# GD32G5x3 register map
File version: 1.0
CPU: CM33 r2p1, little endian, MPU, FPU, 4 interrupt priority bits
Registers are 32-bit, read-write, reset 0x0 unless marked. A register's access mark holds for its fields unless they carry their own. Offsets are from the block's base; [hi:lo] are bit positions.

## QSPI — Quad-SPI interface
Base 0xA0001000
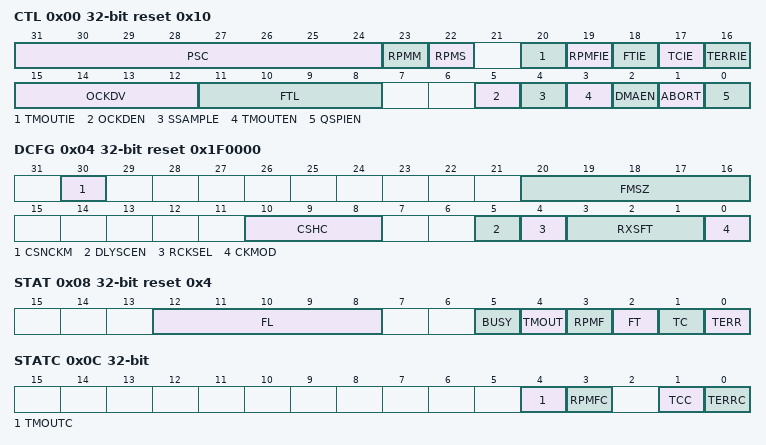
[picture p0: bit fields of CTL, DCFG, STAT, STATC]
0x00 CTL reset 0x10 — Control register
  [31:24] PSC — The clock prescaler of AHB clock for generating SCK
  [23] RPMM — Read polling match mode
  [22] RPMS — Read polling mode stop
  [20] TMOUTIE — Timeout interrupt enable
  [19] RPMFIE — Read polling mode match interrupt enable
  [18] FTIE — FIFO threshold interrupt enable
  [17] TCIE — Transfer complete interrupt enable
  [16] TERRIE — Transfer error interrupt enable
  [15:12] OCKDV — output clock delay value
  [11:8] FTL — FIFO threshold level
  [5] OCKDEN — Output clock delay enable when write data to flash
  [4] SSAMPLE — Sample delay
  [3] TMOUTEN — Timeout counter enable
  [2] DMAEN — DMA enable
  [1] ABORT — Abort request
  [0] QSPIEN — QSPI enable bit
0x04 DCFG reset 0x1F0000 — Device configuration register
  [30] CSNCKM — Select whether the CSN falls and rises one or two SCK clock cycles before the first SCK effective rising edge and after the last SCK effective rising edge
  [20:16] FMSZ — Flash memory size
  [10:8] CSHC — Chip select high cycle
  [5] DLYSCEN — Delay scan enable
  [4] RCKSEL — Receive clock select
  [3:1] RXSFT — Shift receive step if rececive data delay more than 0
  [0] CKMOD — This bit indicates the SCK level when QSPI is free
0x08 STAT access per field reset 0x4 — Status register
  [12:8] FL rw — FIFO level
  [5] BUSY ro — Busy flag
  [4] TMOUT ro — Timeout flag
  [3] RPMF ro — Read polling match flag
  [2] FT ro — FIFO threshold flag
  [1] TC ro — Transfer complete flag
  [0] TERR ro — Transfer error flag
0x0C STATC wo — Status clear register
  [4] TMOUTC — Clear timeout flag
  [3] RPMFC — Clear read polling mode match flag
  [1] TCC — Clear transfer complete flag
  [0] TERRC — Clear transfer error flag
0x10 DTLEN — Data length register
  [31:0] DTLEN — Data length
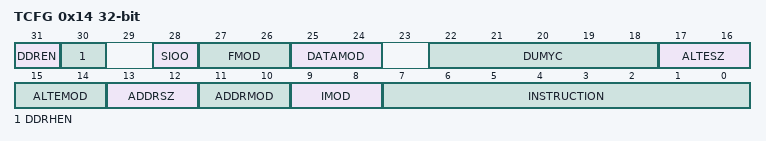
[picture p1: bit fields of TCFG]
0x14 TCFG — Transfer configuration register
  [31] DDREN — Double data rate mode enable
  [30] DDRHEN — DDR output hold enable
  [28] SIOO — Send instruction only once mode
  [27:26] FMOD — Functional mode
  [25:24] DATAMOD — Data mode
  [22:18] DUMYC — Number of dummy cycles
  [17:16] ALTESZ — Alternate bytes size
  [15:14] ALTEMOD — Alternate bytes mode
  [13:12] ADDRSZ — Address size
  [11:10] ADDRMOD — Address mode
  [9:8] IMOD — Instruction mode
  [7:0] INSTRUCTION
0x18 ADDR — Address register
  [31:0] ADDR — Address to be send to the external Flash memory
0x1C ALTE — Alternate bytes register
  [31:0] ALTE — Alternate bytes
0x20 DATA
  [31:0] DATA — Interactive data between QSPI and flash memory
0x24 STATMK — Status mask register
  [31:0] MASK — Status mask in read polling mode
0x28 STATMATCH — Status match register
  [31:0] MATCH — Status match in read polling mode
0x2C INTERVAL
  [15:0] INTERVAL — Interval cycle
0x30 TMOUT — Timeout register
  [15:0] TMOUTCYC — Timeout cycle
0x34 FLUSH wo — FIFO flush register
  [0] FLUSH — Used to flush all qspi interal fifo

## SPI0 — Serial peripheral interface
Base 0x40013000
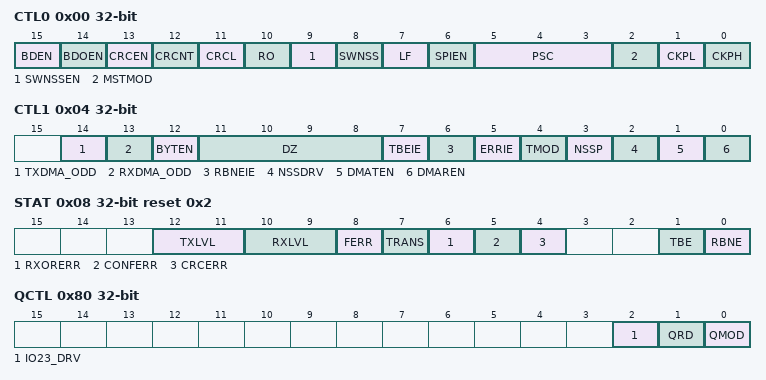
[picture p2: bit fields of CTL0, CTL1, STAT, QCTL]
0x00 CTL0 — control register 0
  [15] BDEN — Bidirectional enable
  [14] BDOEN — Bidirectional Transmit output enable
  [13] CRCEN — Hardware CRC calculation enable
  [12] CRCNT — CRC transfer next
  [11] CRCL — CRC length
  [10] RO — Receive only
  [9] SWNSSEN — NSS Software Mode Selection
  [8] SWNSS — NSS Pin Selection In NSS Software Mode
  [7] LF — LSB First Mode
  [6] SPIEN — SPI enable
  [5:3] PSC — Master Clock Prescaler Selection
  [2] MSTMOD — Master Mode Enable
  [1] CKPL — Clock Polarity Selection
  [0] CKPH — Clock Phase Selection
0x04 CTL1 — control register 1
  [14] TXDMA_ODD — Odd bytes in TX DMA channel
  [13] RXDMA_ODD — Odd bytes in RX DMA channel
  [12] BYTEN — Byte access enable
  [11:8] DZ — Date size
  [7] TBEIE — Transmit Buffer Empty Interrupt Enable
  [6] RBNEIE — Receive Buffer Not Empty Interrupt Enable
  [5] ERRIE — Error interrupt enable
  [4] TMOD — SPI TI Mode Enable
  [3] NSSP — SPI NSS Pulse Mode Enable
  [2] NSSDRV — NSS output enable
  [1] DMATEN — Tx buffer DMA enable
  [0] DMAREN — Rx buffer DMA enable
0x08 STAT access per field reset 0x2 — status register
  [12:11] TXLVL ro — Tx FIFO level
  [10:9] RXLVL ro — Rx FIFO level
  [8] FERR rw — Format Error
  [7] TRANS ro — Transmitting ongoing Bit
  [6] RXORERR ro — Reception Overrun Error Bit
  [5] CONFERR ro — SPI Configuration error
  [4] CRCERR rw — SPI CRC Error Bit
  [1] TBE ro — Transmit Buffer Empty
  [0] RBNE ro — Receive Buffer Not Empty
0x0C DATA
  [15:0] DATA
0x10 CPCPOLY reset 0x7 — CRC polynomial register
  [15:0] CRCPOLY
0x14 RCRC ro — RX CRC register
  [15:0] RCRC — RX RCR register
0x18 TCRC ro — TX CRC register
  [15:0] TCRC — Tx CRC register
0x80 QCTL — SPI quad wird control register
  [2] IO23_DRV — Drive IO2 and IO3 enable
  [1] QRD — Quad wire read select
  [0] QMOD — Quad wire mode enable

## SPI1 — Serial peripheral interface
Base 0x40003800
Registers as SPI0, without QCTL.

## SPI2 — Serial peripheral interface
Base 0x40003C00
Registers as SPI0, without QCTL.
